# bcm2837_lpa register map
Vendor: BROADCOM; Series: BCM2837; File version: A
CPU: CA72 r0p0, little endian, MPU, FPU, 2 interrupt priority bits
Registers are 32-bit, read-write, reset 0x0 unless marked. A register's access mark holds for its fields unless they carry their own. Offsets are from the block's base; [hi:lo] are bit positions; lines under a group give offsets from that group; {n}, {i} and the like mark numbered series; 'fields as' and 'values as' point back to an identical list.

## LIC — Broadcom Legacy Interrupt Controller
Base 0x3F00B000
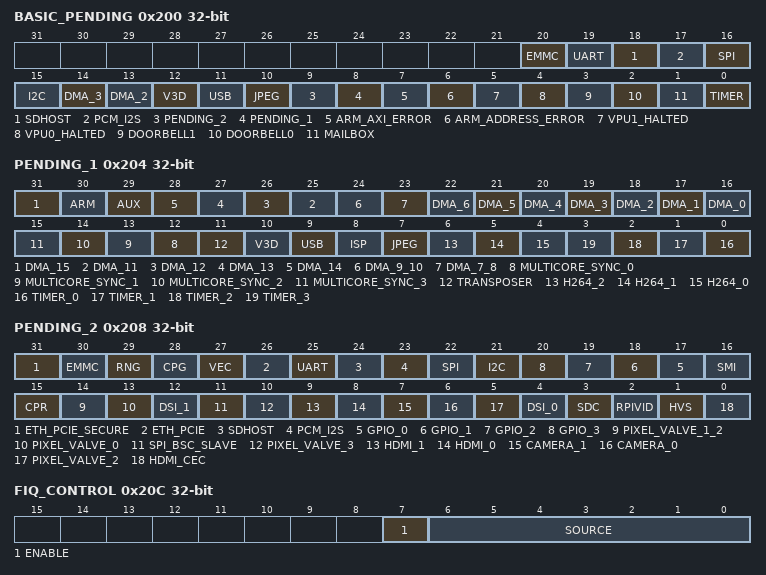
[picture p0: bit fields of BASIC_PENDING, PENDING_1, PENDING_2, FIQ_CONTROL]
0x200 BASIC_PENDING ro — Basic pending info
  [20] EMMC — OR of EMMC and EMMC2
  [19] UART — OR of all PL011 UARTs
  [18] SDHOST
  [17] PCM_I2S
  [16] SPI — OR of all SPI
  [15] I2C — OR of all I2C
  [14] DMA_3
  [13] DMA_2
  [12] V3D
  [11] USB
  [10] JPEG
  [9] PENDING_2 — One or more bits are set in PENDING_2 (ignores 53 - 57, 62)
  [8] PENDING_1 — One or more bits are set in PENDING_1 (ignores 7, 9, 10, 18, 19)
  [7] ARM_AXI_ERROR
  [6] ARM_ADDRESS_ERROR
  [5] VPU1_HALTED
  [4] VPU0_HALTED
  [3] DOORBELL1
  [2] DOORBELL0
  [1] MAILBOX
  [0] TIMER — ARMC Timer
0x204 PENDING_1 ro — Pending state for interrupts 1 - 31
  [31] DMA_15
  [30] ARM
  [29] AUX — OR of UART1, SPI1 and SPI2
  [n+14] DMA_{n} (n=11..14)
  [24] DMA_9_10 — OR of DMA 9 and 10
  [23] DMA_7_8 — OR of DMA 7 and 8
  [n+16] DMA_{n} (n=0..6)
  [n+12] MULTICORE_SYNC_{n} (n=0..3)
  [11] TRANSPOSER
  [10] V3D
  [9] USB
  [8] ISP
  [7] JPEG
  [6] H264_2
  [5] H264_1
  [4] H264_0
  [n] TIMER_{n} (n=0..3)
0x208 PENDING_2 ro — Pending state for interrupts 32 - 63
  [31] ETH_PCIE_SECURE
  [30] EMMC — OR of EMMC and EMMC2
  [29] RNG
  [28] CPG
  [27] VEC
  [26] ETH_PCIE — OR of all ETH_PCIe L2
  [25] UART — OR of all PL011 UARTs
  [24] SDHOST
  [23] PCM_I2S
  [22] SPI — OR of all SPI
  [21] I2C — OR of all I2C
  [n+17] GPIO_{n} (n=0..3)
  [16] SMI
  [15] CPR
  [14] PIXEL_VALVE_1_2 — OR of Pixel Valve 1 and 2
  [13] PIXEL_VALVE_0
  [12] DSI_1
  [11] SPI_BSC_SLAVE
  [10] PIXEL_VALVE_3
  [9] HDMI_1
  [8] HDMI_0
  [7] CAMERA_1
  [6] CAMERA_0
  [5] PIXEL_VALVE_2
  [4] DSI_0
  [3] SDC
  [2] RPIVID
  [1] HVS
  [0] HDMI_CEC
0x20C FIQ_CONTROL
  [7] ENABLE — FIQ Enable
  [6:0] SOURCE — FIQ Source
    {v}=TIMER_{v} (v=0..3); 4=H264_0; 5=H264_1; 6=H264_2; 7=JPEG; 8=ISP; 9=USB; 10=V3D; 11=TRANSPOSER; {v}=MULTICORE_SYNC_{v-12} (v=12..15); {v}=DMA_{v-16} (v=16..22); 23=DMA_7_8 (OR of DMA 7 and 8); 24=DMA_9_10 (OR of DMA 9 and 10); {v}=DMA_{v-14} (v=25..28); 29=AUX (OR of UART1, SPI1 and SPI2); 30=ARM; 31=DMA_15; 32=HDMI_CEC; 33=HVS; 34=RPIVID; 35=SDC; 36=DSI_0; 37=PIXEL_VALVE_2; 38=CAMERA_0; 39=CAMERA_1; 40=HDMI_0; 41=HDMI_1; 42=PIXEL_VALVE_3; 43=SPI_BSC_SLAVE; 44=DSI_1; 45=PIXEL_VALVE_0; 46=PIXEL_VALVE_1_2 (OR of Pixel Valve 1 and 2); 47=CPR; 48=SMI; {v}=GPIO_{v-49} (v=49..52); 53=I2C (OR of all I2C); 54=SPI (OR of all SPI); 55=PCM_I2S; 56=SDHOST; 57=UART (OR of all PL011 UARTs); 58=ETH_PCIE (OR of all ETH_PCIe L2); 59=VEC; 60=CPG; 61=RNG; 62=EMMC (OR of EMMC and EMMC2); 63=ETH_PCIE_SECURE; 64=TIMER (ARMC Timer); 65=MAILBOX; 66=DOORBELL0; 67=DOORBELL1; 68=VPU0_HALTED; 69=VPU1_HALTED; 70=ARM_ADDRESS_ERROR; 71=ARM_AXI_ERROR
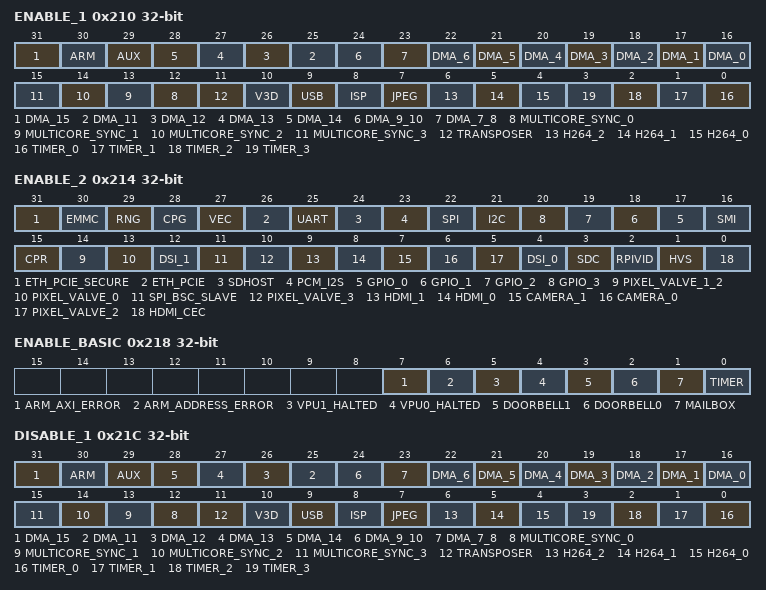
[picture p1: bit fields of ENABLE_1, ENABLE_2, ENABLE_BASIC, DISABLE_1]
0x210 ENABLE_1 write-1-sets — Enable interrupts 1 - 31
  fields as PENDING_1
0x214 ENABLE_2 write-1-sets — Enable interrupts 32 - 63
  fields as PENDING_2
0x218 ENABLE_BASIC write-1-sets — Enable basic interrupts
  [7] ARM_AXI_ERROR
  [6] ARM_ADDRESS_ERROR
  [5] VPU1_HALTED
  [4] VPU0_HALTED
  [3] DOORBELL1
  [2] DOORBELL0
  [1] MAILBOX
  [0] TIMER — ARMC Timer
0x21C DISABLE_1 write-1-clears — Disable interrupts 1 - 31
  fields as PENDING_1
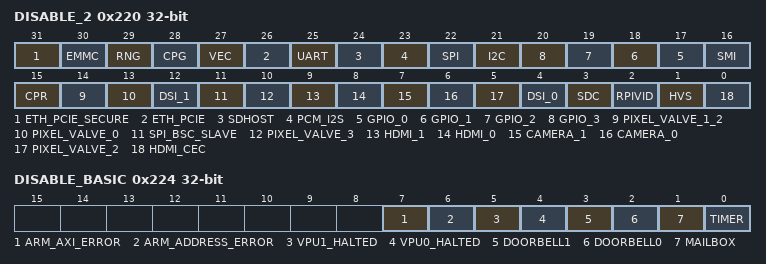
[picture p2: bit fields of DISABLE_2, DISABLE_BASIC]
0x220 DISABLE_2 write-1-clears — Disable interrupts 32 - 63
  fields as PENDING_2
0x224 DISABLE_BASIC write-1-clears — Disable basic interrupts
  fields as ENABLE_BASIC

## USB_OTG_HOST — USB on the go high speed
Base 0x3F980400
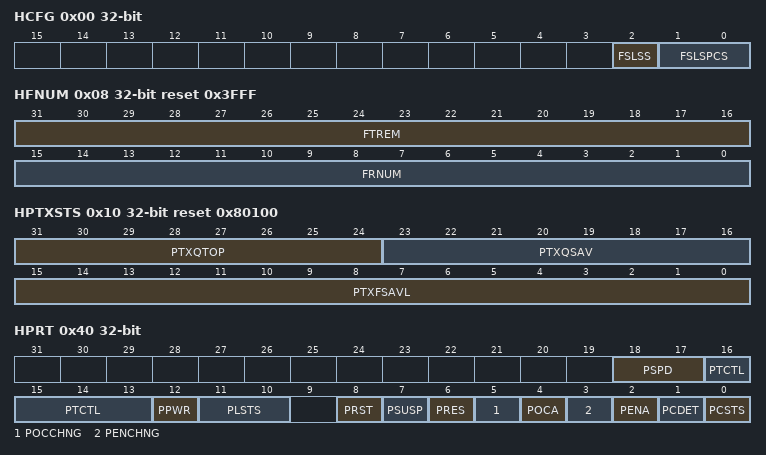
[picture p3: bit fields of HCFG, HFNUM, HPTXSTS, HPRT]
0x00 HCFG access per field — OTG_HS host configuration register
  [2] FSLSS ro — FS- and LS-only support
  [1:0] FSLSPCS rw — FS/LS PHY clock select
0x04 HFIR reset 0xEA60 — OTG_HS Host frame interval register
  [15:0] FRIVL — Frame interval
0x08 HFNUM ro reset 0x3FFF — OTG_HS host frame number/frame time remaining register
  [31:16] FTREM — Frame time remaining
  [15:0] FRNUM — Frame number
0x10 HPTXSTS access per field reset 0x80100 — Host periodic transmit FIFO/queue status register
  [31:24] PTXQTOP ro — Top of the periodic transmit request queue
  [23:16] PTXQSAV ro — Periodic transmit request queue space available
  [15:0] PTXFSAVL rw — Periodic transmit data FIFO space available
0x14 HAINT ro — OTG_HS Host all channels interrupt register
  [15:0] HAINT — Channel interrupts
0x18 HAINTMSK — OTG_HS host all channels interrupt mask register
  [15:0] HAINTM — Channel interrupt mask
0x40 HPRT access per field — OTG_HS host port control and status register
  [18:17] PSPD ro — Port speed
  [16:13] PTCTL rw — Port test control
  [12] PPWR rw — Port power
  [11:10] PLSTS ro — Port line status
  [8] PRST rw — Port reset
  [7] PSUSP rw — Port suspend
  [6] PRES rw — Port resume
  [5] POCCHNG rw — Port overcurrent change
  [4] POCA ro — Port overcurrent active
  [3] PENCHNG rw — Port enable/disable change
  [2] PENA rw — Port enable
  [1] PCDET rw — Port connect detected
  [0] PCSTS ro — Port connect status
{0x100+0x20*i} HOST_CHANNEL{i} (i=0..11) group — Host channel {i}
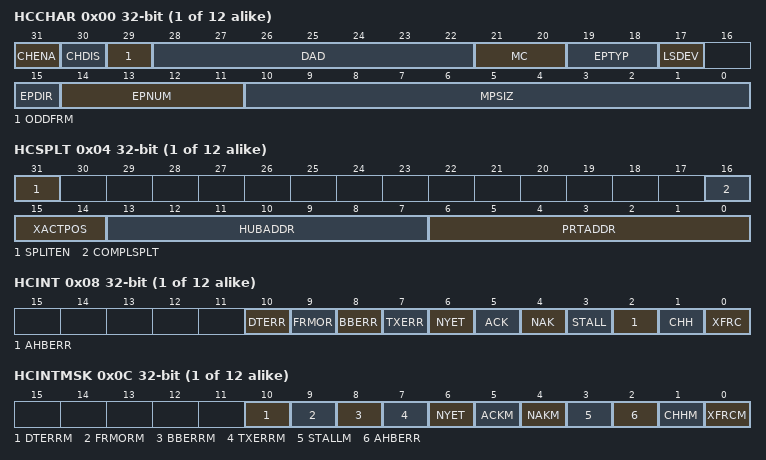
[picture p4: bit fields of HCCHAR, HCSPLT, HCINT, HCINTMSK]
  0x00 HCCHAR — Characteristics register
    [31] CHENA — Channel enable
    [30] CHDIS — Channel disable
    [29] ODDFRM — Odd frame
    [28:22] DAD — Device address
    [21:20] MC — Multi Count (MC) / Error Count (EC)
    [19:18] EPTYP — Endpoint type
    [17] LSDEV — Low-speed device
    [15] EPDIR — Endpoint direction
    [14:11] EPNUM — Endpoint number
    [10:0] MPSIZ — Maximum packet size
  0x04 HCSPLT — Split control register
    [31] SPLITEN — Split enable
    [16] COMPLSPLT — Do complete split
    [15:14] XACTPOS
    [13:7] HUBADDR — Hub address
    [6:0] PRTADDR — Port address
  0x08 HCINT — Interrupt register
    [10] DTERR — Data toggle error
    [9] FRMOR — Frame overrun
    [8] BBERR — Babble error
    [7] TXERR — Transaction error
    [6] NYET — Response received interrupt
    [5] ACK — ACK response received/transmitted interrupt
    [4] NAK — NAK response received interrupt
    [3] STALL — STALL response received interrupt
    [2] AHBERR — AHB error
    [1] CHH — Channel halted
    [0] XFRC — Transfer completed
  0x0C HCINTMSK — Interrupt mask
    [10] DTERRM — Data toggle error mask
    [9] FRMORM — Frame overrun mask
    [8] BBERRM — Babble error mask
    [7] TXERRM — Transaction error mask
    [6] NYET — response received interrupt mask
    [5] ACKM — ACK response received/transmitted interrupt mask
    [4] NAKM — NAK response received interrupt mask
    [3] STALLM — STALL response received interrupt mask
    [2] AHBERR — AHB error
    [1] CHHM — Channel halted mask
    [0] XFRCM — Transfer completed mask
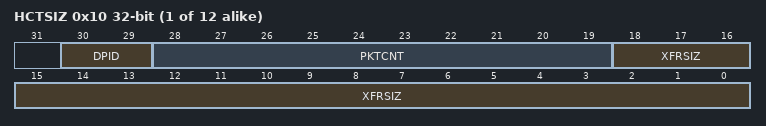
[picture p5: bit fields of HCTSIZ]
  0x10 HCTSIZ — Transfer size
    [30:29] DPID — Data PID
    [28:19] PKTCNT — Packet count
    [18:0] XFRSIZ — Transfer size
  0x14 HCDMA — DMA address
    [31:0] DMAADDR

## USB_OTG_PWRCLK — USB on the go high speed power control
Base 0x3F980E00
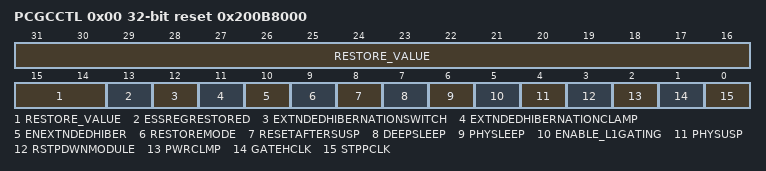
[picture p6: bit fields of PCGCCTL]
0x00 PCGCCTL reset 0x200B8000 — power and clock gating control
  [31:14] RESTORE_VALUE
  [13] ESSREGRESTORED — Essential register values restored
  [12] EXTNDEDHIBERNATIONSWITCH — Extended hibernation switch
  [11] EXTNDEDHIBERNATIONCLAMP — Extended hibernation clamp
  [10] ENEXTNDEDHIBER — Enable extended hibernation
  [9] RESTOREMODE
  [8] RESETAFTERSUSP — Reset after suspend
  [7] DEEPSLEEP — PHY is in deep sleep
  [6] PHYSLEEP — PHY is in sleep mode
  [5] ENABLE_L1GATING — Enable sleep clock gating
  [4] PHYSUSP — PHY Suspended
  [3] RSTPDWNMODULE — Power down modules
  [2] PWRCLMP — Power clamp
  [1] GATEHCLK
  [0] STPPCLK — Stop PHY clock
